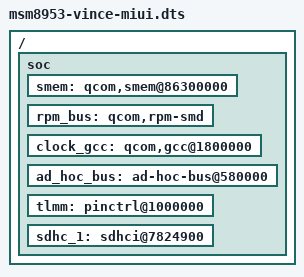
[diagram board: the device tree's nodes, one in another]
/*
 * Copyright (c) 2015-2017, The Linux Foundation. All rights reserved.
 * Copyright (C) 2019 XiaoMi, Inc.
 *
 * This program is free software; you can redistribute it and/or modify
 * it under the terms of the GNU General Public License version 2 and
 * only version 2 as published by the Free Software Foundation.
 *
 * This program is distributed in the hope that it will be useful,
 * but WITHOUT ANY WARRANTY; without even the implied warranty of
 * MERCHANTABILITY or FITNESS FOR A PARTICULAR PURPOSE.  See the
 * GNU General Public License for more details.
 */

/dts-v1/;

/ {

	soc: soc {
		/*
		 * The ordering of these devices is important to boot time
		 * for iot projects.
		 */
		smem: qcom,smem@86300000 {};
		rpm_bus: qcom,rpm-smd {};
		clock_gcc: qcom,gcc@1800000 {};
		ad_hoc_bus: ad-hoc-bus@580000 {};
		tlmm: pinctrl@1000000 {};
		sdhc_1: sdhci@7824900 {};
	};
};

#include "msm8953-vince-miui.dtsi"
#include "vince/overlay.dtsi"
